# STM32H743 register map
File version: 2.4
CPU: CM7 r0p1, little endian, MPU, FPU, 4 interrupt priority bits
Registers are 32-bit, read-write, reset 0x0 unless marked. A register's access mark holds for its fields unless they carry their own. Offsets are from the block's base; [hi:lo] are bit positions; {n}, {i} and the like mark numbered series; 'fields as' and 'values as' point back to an identical list.

## HRTIM_TIMD — 高分辨率定时器：TIMD
Base 0x40017600
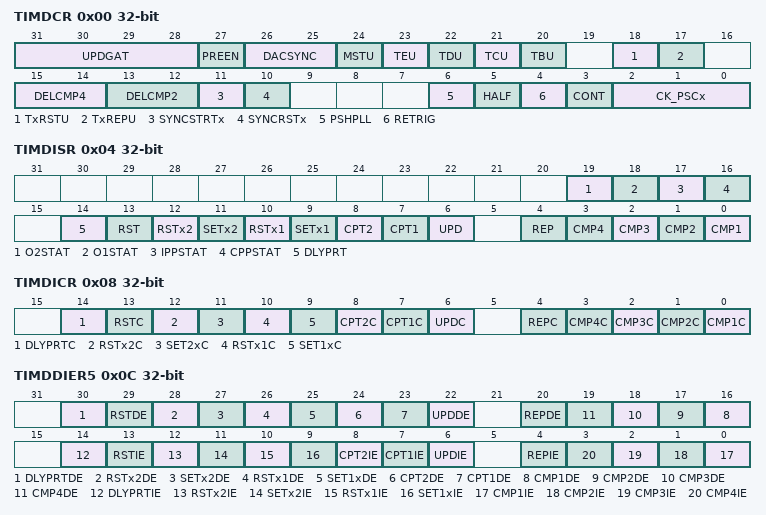
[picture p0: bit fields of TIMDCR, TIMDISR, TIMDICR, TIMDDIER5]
0x00 TIMDCR — Timerx 控制寄存器
  [31:28] UPDGAT — 更新门控
  [27] PREEN — 预装载使能
  [26:25] DACSYNC — DAC 同步
  [24] MSTU — 主定时器更新
  [23] TEU — 定时器 E 更新
  [22] TDU — 定时器 D 更新
  [21] TCU — 定时器 C 更新
  [20] TBU — 定时器 B 更新
  [18] TxRSTU — Timerx 复位更新
  [17] TxREPU — Timer x 重复计数器更新
  [15:14] DELCMP4 — 延迟 CMP4 模式
  [13:12] DELCMP2 — 延迟 CMP2 模式
  [11] SYNCSTRTx — 同步启动 Timer x
  [10] SYNCRSTx — 同步复位 Timer x
  [6] PSHPLL — 推挽模式使能
  [5] HALF — 半模式使能
  [4] RETRIG — 可重触发模式
  [3] CONT — 连续模式
  [2:0] CK_PSCx — HRTIM Timer x 时钟预分频器
0x04 TIMDISR ro — Timerx 中断状态寄存器
  [19] O2STAT — 输出 2 状态
  [18] O1STAT — 输出 1 状态
  [17] IPPSTAT — 空闲推挽状态
  [16] CPPSTAT — 当前推挽状态
  [14] DLYPRT — 延迟保护标志
  [13] RST — 复位中断标志
  [12] RSTx2 — 输出 2 复位中断标志
  [11] SETx2 — 输出 2 置位中断标志
  [10] RSTx1 — 输出 1 复位中断标志
  [9] SETx1 — 输出 1 置位中断标志
  [8] CPT2 — 捕获 2 中断标志
  [7] CPT1 — 捕获 1 中断标志
  [6] UPD — 更新中断标志
  [4] REP — 重复计数器中断标志
  [n-1] CMP{n} (n=1..4) — 比较 {n} 中断标志
0x08 TIMDICR wo — Timerx 中断清除寄存器
  [14] DLYPRTC — 延迟保护标志清除
  [13] RSTC — 复位中断标志清除
  [12] RSTx2C — 输出 2 复位标志清除
  [11] SET2xC — 输出 2 置位标志清除
  [10] RSTx1C — 输出 1 复位标志清除
  [9] SET1xC — 输出 1 置位标志清除
  [8] CPT2C — 捕获 2 中断标志清除
  [7] CPT1C — 捕获 1 中断标志清除
  [6] UPDC — 更新中断标志清除
  [4] REPC — 重复计数器中断标志清除
  [n-1] CMP{n}C (n=1..4) — 比较 {n} 中断标志清除
0x0C TIMDDIER5 — TIMxDIER5
  [30] DLYPRTDE — 延迟保护 DMA 使能
  [29] RSTDE — 复位 DMA 使能
  [28] RSTx2DE — 输出 2 复位 DMA 使能
  [27] SETx2DE — 输出 2 置位 DMA 使能
  [26] RSTx1DE — 输出 1 复位 DMA 使能
  [25] SET1xDE — 输出 1 置位 DMA 使能
  [24] CPT2DE — 捕获 2 DMA 使能
  [23] CPT1DE — 捕获 1 DMA 使能
  [22] UPDDE — 更新 DMA 使能
  [20] REPDE — 重复计数器 DMA 使能
  [n+15] CMP{n}DE (n=1..4) — 比较 {n} DMA 使能
  [14] DLYPRTIE — 延迟保护中断使能
  [13] RSTIE — 复位中断使能
  [12] RSTx2IE — 输出 2 复位中断使能
  [11] SETx2IE — 输出 2 置位中断使能
  [10] RSTx1IE — 输出 1 复位中断使能
  [9] SET1xIE — 输出 1 置位中断使能
  [8] CPT2IE — 捕获 2 中断使能
  [7] CPT1IE — 捕获 1 中断使能
  [6] UPDIE — 更新中断使能
  [4] REPIE — 重复计数器中断使能
  [n-1] CMP{n}IE (n=1..4) — 比较 {n} 中断使能
0x10 CNTDR — Timerx 计数器寄存器
  [15:0] CNTx — Timerx 计数器值
0x14 PERDR reset 0xFFFF — Timerx 周期寄存器
  [15:0] PERx — Timerx 周期值
0x18 REPDR — Timerx 重复计数器寄存器
  [7:0] REPx — Timerx 重复计数器值
0x1C CMP1DR — Timerx 比较寄存器 1
  [15:0] CMP1x — Timerx 比较值 1
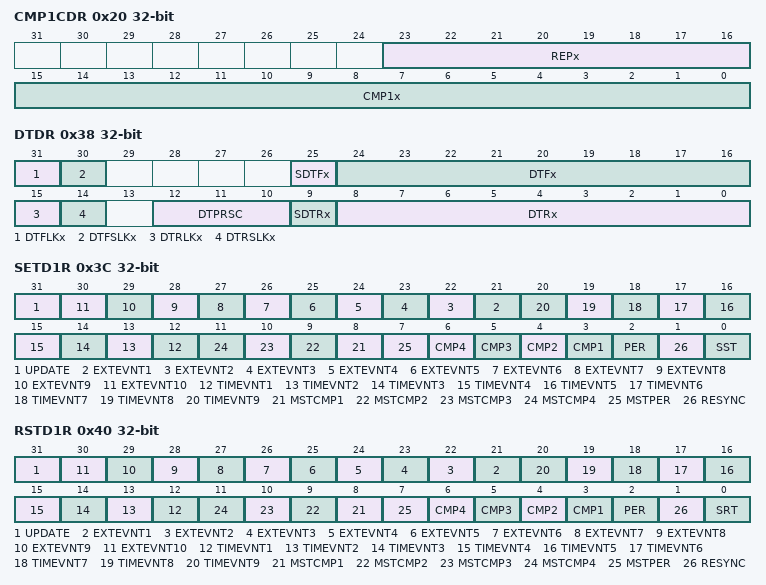
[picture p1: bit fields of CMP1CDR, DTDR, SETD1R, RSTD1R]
0x20 CMP1CDR — Timerx 比较复合寄存器 1
  [23:16] REPx — Timerx 重复计数器值（从 HRTIM_REPx 寄存器别名映射）
  [15:0] CMP1x — Timerx 比较值 1
{0x1C+4i} CMP{i}DR (i=2..4) — Timerx 比较寄存器 {i}
  [15:0] CMP{i}x — Timerx 比较值 {i}
0x30 CPT1DR ro — Timerx 捕获寄存器 1
  [15:0] CPT1x — Timerx 捕获值 1
0x34 CPT2DR ro — Timerx 捕获寄存器 2
  [15:0] CPT2x — Timerx 捕获值 2
0x38 DTDR — Timerx 死区时间寄存器
  [31] DTFLKx — 死区下降沿锁定
  [30] DTFSLKx — 死区下降沿符号锁定
  [25] SDTFx — 死区下降沿符号值
  [24:16] DTFx — 死区下降沿值
  [15] DTRLKx — 死区上升沿锁定
  [14] DTRSLKx — 死区上升沿符号锁定
  [12:10] DTPRSC — 死区预分频器
  [9] SDTRx — 死区上升沿符号值
  [8:0] DTRx — 死区上升沿值
0x3C SETD1R — Timerx 输出 1 置位寄存器
  [31] UPDATE — 寄存器更新（预装载传输至活跃寄存器）
  [n+20] EXTEVNT{n} (n=1..10) — 外部事件 {n}
  [n+11] TIMEVNT{n} (n=1..9) — 定时器事件 {n}
  [n+7] MSTCMP{n} (n=1..4) — 主定时器比较 {n}
  [7] MSTPER — 主定时器周期
  [n+2] CMP{n} (n=1..4) — Timer A 比较 {n}
  [2] PER — Timer A 周期
  [1] RESYNC — Timer A 再同步
  [0] SST — 软件置位触发
0x40 RSTD1R — Timerx 输出 1 复位寄存器
  [31] UPDATE — 寄存器更新
  [n+20] EXTEVNT{n} (n=1..10) — 外部事件 {n}
  [n+11] TIMEVNT{n} (n=1..9) — 定时器事件 {n}
  [n+7] MSTCMP{n} (n=1..4) — 主定时器比较 {n}
  [7] MSTPER — 主定时器周期
  [n+2] CMP{n} (n=1..4) — Timer A 比较 {n}
  [2] PER — Timer A 周期
  [1] RESYNC — Timer A 再同步
  [0] SRT — 软件复位触发
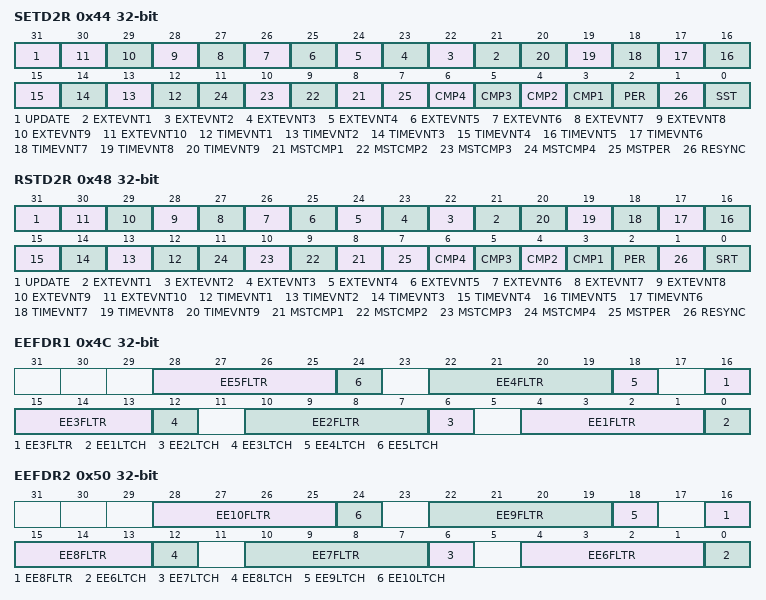
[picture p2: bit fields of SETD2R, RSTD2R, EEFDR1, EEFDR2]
0x44 SETD2R — Timerx 输出 2 置位寄存器
  [31] UPDATE — 寄存器更新
  [n+20] EXTEVNT{n} (n=1..10) — 外部事件 {n}
  [n+11] TIMEVNT{n} (n=1..9) — 定时器事件 {n}
  [n+7] MSTCMP{n} (n=1..4) — 主定时器比较 {n}
  [7] MSTPER — 主定时器周期
  [n+2] CMP{n} (n=1..4) — Timer A 比较 {n}
  [2] PER — Timer A 周期
  [1] RESYNC — Timer A 再同步
  [0] SST — 软件置位触发
0x48 RSTD2R — Timerx 输出 2 复位寄存器
  fields as RSTD1R
0x4C EEFDR1 — Timerx 外部事件滤波寄存器 1
  [6n-2:6n-5] EE{n}FLTR (n=1..5) — 外部事件 {n} 滤波器
  [6n-6] EE{n}LTCH (n=1..5) — 外部事件 {n} 锁存器
0x50 EEFDR2 — Timerx 外部事件滤波寄存器 2
  [6n-32:6n-35] EE{n}FLTR (n=6..10) — 外部事件 {n} 滤波器
  [6n-36] EE{n}LTCH (n=6..10) — 外部事件 {n} 锁存器
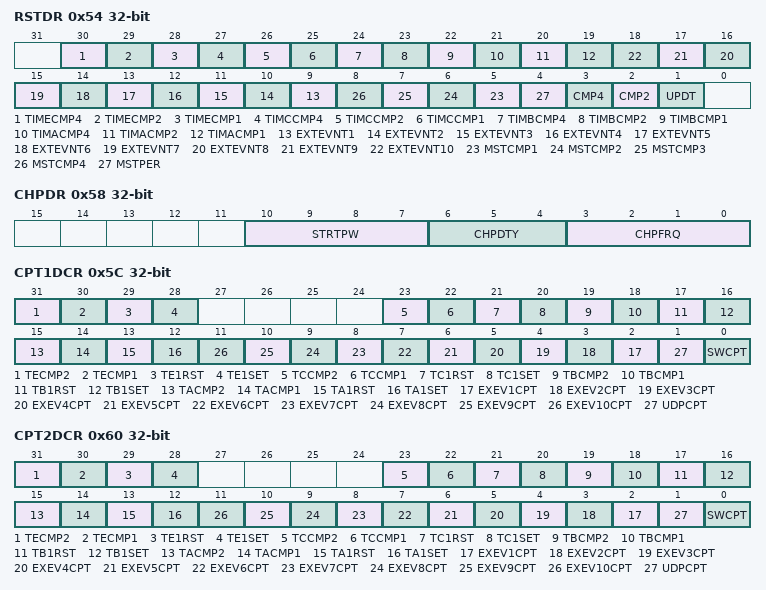
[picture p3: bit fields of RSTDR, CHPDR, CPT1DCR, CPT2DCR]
0x54 RSTDR — TimerA 复位寄存器
  [30] TIMECMP4 — Timer E 比较 4
  [29] TIMECMP2 — Timer E 比较 2
  [28] TIMECMP1 — Timer E 比较 1
  [27] TIMCCMP4 — Timer C 比较 4
  [26] TIMCCMP2 — Timer C 比较 2
  [25] TIMCCMP1 — Timer C 比较 1
  [24] TIMBCMP4 — Timer B 比较 4
  [23] TIMBCMP2 — Timer B 比较 2
  [22] TIMBCMP1 — Timer B 比较 1
  [21] TIMACMP4 — Timer A 比较 4
  [20] TIMACMP2 — Timer A 比较 2
  [19] TIMACMP1 — Timer A 比较 1
  [n+8] EXTEVNT{n} (n=1..10) — 外部事件 {n}
  [n+4] MSTCMP{n} (n=1..4) — 主定时器比较 {n}
  [4] MSTPER — 主定时器周期
  [3] CMP4 — Timer A 比较 4 复位
  [2] CMP2 — Timer A 比较 2 复位
  [1] UPDT — Timer A 更新复位
0x58 CHPDR — Timerx 斩波寄存器
  [10:7] STRTPW — 脉冲宽度起步
  [6:4] CHPDTY — Timerx 斩波占空比值
  [3:0] CHPFRQ — Timerx 载波频率值
0x5C CPT1DCR — Timerx 捕获 1 控制寄存器
  [31] TECMP2 — Timer E 比较 2
  [30] TECMP1 — Timer E 比较 1
  [29] TE1RST — Timer E 输出 1 复位
  [28] TE1SET — Timer E 输出 1 置位
  [23] TCCMP2 — Timer C 比较 2
  [22] TCCMP1 — Timer C 比较 1
  [21] TC1RST — Timer C 输出 1 复位
  [20] TC1SET — Timer C 输出 1 置位
  [19] TBCMP2 — Timer B 比较 2
  [18] TBCMP1 — Timer B 比较 1
  [17] TB1RST — Timer B 输出 1 复位
  [16] TB1SET — Timer B 输出 1 置位
  [15] TACMP2 — Timer A 比较 2
  [14] TACMP1 — Timer A 比较 1
  [13] TA1RST — Timer A 输出 1 复位
  [12] TA1SET — Timer A 输出 1 置位
  [n+1] EXEV{n}CPT (n=1..10) — 外部事件 {n} 捕获
  [1] UDPCPT — 更新捕获
  [0] SWCPT — 软件捕获
0x60 CPT2DCR — Timerx 捕获 2 控制寄存器
  fields as CPT1DCR
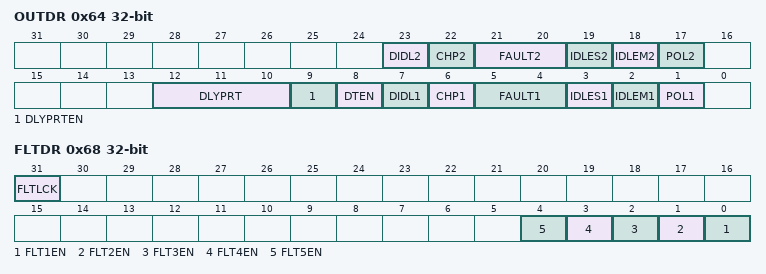
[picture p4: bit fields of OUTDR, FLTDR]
0x64 OUTDR — Timerx 输出寄存器
  [23] DIDL2 — 输出 2 突发模式空闲进入时的死区时间
  [22] CHP2 — 输出 2 斩波使能
  [21:20] FAULT2 — 输出 2 故障状态
  [19] IDLES2 — 输出 2 空闲状态
  [18] IDLEM2 — 输出 2 空闲模式
  [17] POL2 — 输出 2 极性
  [12:10] DLYPRT — 延迟保护
  [9] DLYPRTEN — 延迟保护使能
  [8] DTEN — 死区使能
  [7] DIDL1 — 输出 1 突发模式空闲进入时的死区时间
  [6] CHP1 — 输出 1 斩波使能
  [5:4] FAULT1 — 输出 1 故障状态
  [3] IDLES1 — 输出 1 空闲状态
  [2] IDLEM1 — 输出 1 空闲模式
  [1] POL1 — 输出 1 极性
0x68 FLTDR — Timerx 故障寄存器
  [31] FLTLCK — 故障源锁定
  [n-1] FLT{n}EN (n=1..5) — 故障 {n} 使能
